# SN32F420 register map
Vendor: SONiX Technology Co., Ltd.; Series: SN32F420; File version: 1.00
CPU: CM0 r0p0, little endian, no MPU, no FPU, 2 interrupt priority bits
Registers are 32-bit, read-write, reset 0x0 unless marked. A register's access mark holds for its fields unless they carry their own. Offsets are from the block's base; [hi:lo] are bit positions; 'fields as' and 'values as' point back to an identical list.

## SN_UT16B0 — 16-bit Timer 0 with General Capture function
Base 0x40002000
Same registers: SN_UT16B1 0x40004000
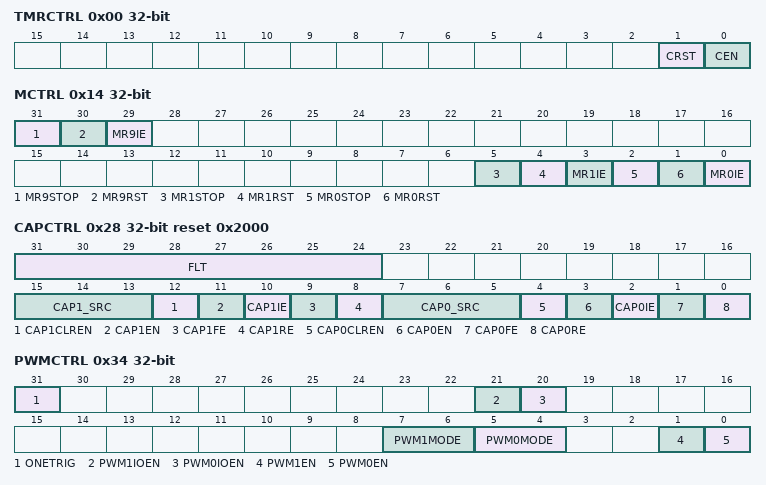
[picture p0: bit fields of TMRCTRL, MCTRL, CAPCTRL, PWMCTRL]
0x00 TMRCTRL — Offset:0x00 UT16Bn Timer Control register
  [1] CRST — Counter Reset
    0=Disable counter reset; 1=Reset Counter (Timer Counter and the Prescale Counter are synchronously reset on the next positive edge of PCLK)
  [0] CEN — Counter enable
    0=Disable counter; 1=Enable Timer Counter and Prescale Counter for counting
0x04 TC — Offset:0x04 UT16Bn Timer Counter register
  [15:0] TC — Timer Counter
0x08 PRE — Offset:0x08 UT16Bn Prescale register
  [7:0] PRE — Prescaler
0x0C PC — Offset:0x0C UT16Bn Prescale Counter register
  [7:0] PC — Prescaler Counter
0x10 CNTCTRL — Offset:0x10 UT16Bn Counter Control register
  [2:0] CTM — Counter/Timer Mode
    0=Timer Mode: every rising PCLK edge; 1=Counter Mode 1 (TC is incremented on rising edges on the CAP0_SIG); 2=Counter Mode 2 (TC is incremented on falling edges on the CAP0_SIG); 3=Counter Mode 3 (TC is incremented on both edges on the CAP0_SIG); 4=Counter Mode 4 (TC is incremented on rising edges on the CAP1_SIG); 5=Counter Mode 5 (TC is incremented on falling edges on the CAP1_SIG); 6=Counter Mode 6 (TC is incremented on both edges on the CAP1_SIG)
0x14 MCTRL — Offset:0x14 UT16Bn Match Control register
  [31] MR9STOP — Stop TC and PC and clear CEN bit when MR9 matches TC
    0=Disable stop TC and PC; 1=Enable (Stop TC and PC and clear CEN bit when MR9 matches TC)
  [30] MR9RST — Enable reset TC when MR9 matches TC
    0=Disable reset TC; 1=Enable (Reset TC when MR9 matches TC)
  [29] MR9IE — Enable generating an interrupt based on CM[2:0] when MR9 matches the value in the TC
    0=Disable generating an interrupt; 1=Enable (Generating an interrupt when MR9 matches TC)
  [5] MR1STOP — Stop TC and PC and clear CEN bit when MR1 matches TC
    0=Disable stop TC and PC; 1=Enable (Stop TC and PC and clear CEN bit when MR1 matches TC)
  [4] MR1RST — Enable reset TC when MR1 matches TC
    0=Disable reset TC; 1=Enable (Reset TC when MR1 matches TC)
  [3] MR1IE — Enable generating an interrupt when MR1 matches TC
    0=Disable generating an interrupt; 1=Enable (Generating an interrupt when MR1 matches TC)
  [2] MR0STOP — Stop TC and PC and clear CEN bit when MR0 matches TC
    0=Disable stop TC and PC; 1=Enable (Stop TC and PC and clear CEN bit when MR0 matches TC)
  [1] MR0RST — Enable reset TC when MR0 matches TC
    0=Disable reset TC; 1=Enable (Reset TC when MR0 matches TC)
  [0] MR0IE — Enable generating an interrupt when MR0 matches TC
    0=Disable generating an interrupt; 1=Enable (Generating an interrupt when MR0 matches TC)
0x18 MR0 — Offset:0x18 UT16Bn MR0 register
  [15:0] MR — Timer counter match value
0x1C MR1 — Offset:0x1C UT16Bn MR1 register
  [15:0] MR — Timer counter match value
0x28 CAPCTRL reset 0x2000 — Offset:0x28 UT16Bn Capture Control register
  [31:24] FLT — Filter width setting for CAP0/1 signal
  [15:13] CAP1_SRC — Signal source of capture event
    0=CAP0_F (Select the CAP0_F as signal source of CAP1_SIG); 1=CAP1_F (Select the CAP1_F as signal source of CAP1_SIG); 2=CAP_XOR (Select CAP0_F XOR CAP1_F as signal source of CAP1_SIG); 3=CMP0 OUT (Select CMP0 OUT as signal source of CAP1_SIG); 4=CMP1 OUT (Select CMP1 OUT as signal source of CAP1_SIG)
  [12] CAP1CLREN — Enable reset TC when capture event occurs.
    0=Disable reset TC when capture event occurs; 1=Enable reset TC when capture event occurs
  [11] CAP1EN — CAP1 function enable
    0=Disable capture function; 1=Enable CAP1 function for external Capture pin
  [10] CAP1IE — Interrupt on UT16Bn_CAP1 event
    0=Disable interrupt; 1=Enable (A CAP0 load due to a UT16Bn_CAP1 event will generate an interrupt.)
  [9] CAP1FE — Capture/Reset on UT16Bn_CAP1 signal falling edge
    0=Disable (No action); 1=Enable (Capture on CAP1_SIG falling edge)
  [8] CAP1RE — Capture/Reset on UT16Bn_CAP1 signal rising edge
    0=Disable (No action); 1=Enable (Capture on CAP1_SIG rising edge)
  [7:5] CAP0_SRC — Signal source of capture event
    0=CAP0_F (Select the CAP0_F as signal source of CAP0_SIG); 1=CAP1_F (Select the CAP1_F as signal source of CAP0_SIG); 2=CAP_XOR (Select CAP0_F XOR CAP1_F as signal source of CAP0_SIG); 3=CMP0 OUT (Select CMP0 OUT as signal source of CAP0_SIG); 4=CMP1 OUT (Select CMP1 OUT as signal source of CAP0_SIG)
  [4] CAP0CLREN — Enable reset TC when capture event occurs.
    values as CAP1CLREN
  [3] CAP0EN — CAP0 function enable
    0=Disable capture function; 1=Enable CAP0 function for external Capture pin
  [2] CAP0IE — Interrupt on UT16Bn_CAP0 event
    0=Disable interrupt; 1=Enable (A CAP0 load due to a UT16Bn_CAP0 event will generate an interrupt.)
  [1] CAP0FE — Capture/Reset on UT16Bn_CAP0 signal falling edge
    0=Disable (No action); 1=Enable (Capture on CAP0_SIG falling edge)
  [0] CAP0RE — Capture/Reset on UT16Bn_CAP0 signal rising edge
    0=Disable (No action); 1=Enable (Capture on CAP0_SIG rising edge)
0x2C CAP0 ro — Offset:0x2C UT16Bn CAP0 register
  [15:0] CAP0 — Timer counter capture value
0x30 CAP1 ro — Offset:0x30 UT16Bn CAP1 register
  [15:0] CAP1 — Timer counter capture value
0x34 PWMCTRL — Offset:0x34 UT16Bn PWM Control register
  [31] ONETRIG — One trigger mode
    0=Disable one trigger mode; 1=Enable one trigger mode
  [21] PWM1IOEN — UT16Bn_PWM1/GPIO selection
    0=Disable (UT16Bn_PWM1 pin is act as GPIO); 1=Enable (UT16Bn_PWM1 pin act as match output, and output depends on PWM1EN bit)
  [20] PWM0IOEN — UT16Bn_PWM0/GPIO selection
    0=Disable (UT16Bn_PWM0 pin is act as GPIO); 1=Enable (UT16Bn_PWM0 pin act as match output, and output depends on PWM0EN bit)
  [7:6] PWM1MODE — PWM1 output mode
    0=PWM mode 1 (During up-counting, PWM1 is 0 when TC is less than MR1.); 1=PWM mode 2 (During up-counting, PWM1 is 1 when TC is less than MR1.); 2=Force 0 (PWM1 is forced to 0); 3=Force 1 (PWM1 is forced to 1)
  [5:4] PWM0MODE — PWM0 output mode
    0=PWM mode 1 (During up-counting, PWM0 is 0 when TC is less than MR0.); 1=PWM mode 2 (During up-counting, PWM0 is 1 when TC is less than MR0.); 2=Force 0 (PWM0 is forced to 0); 3=Force 1 (PWM0 is forced to 1)
  [1] PWM1EN — PWM1 enable
    0=Disable PWM mode for UT16Bn_PWM1; 1=Enable PWM mode for UT16Bn_PWM1
  [0] PWM0EN — PWM0 enable
    0=Disable PWM mode for UT16Bn_PWM0; 1=Enable PWM mode for UT16Bn_PWM0
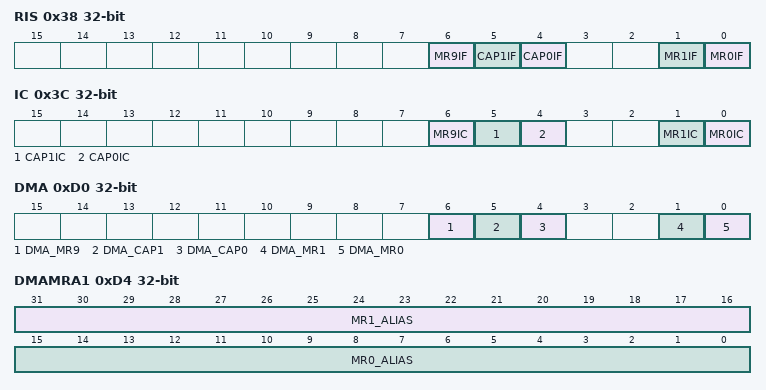
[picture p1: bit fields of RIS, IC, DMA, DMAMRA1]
0x38 RIS ro — Offset:0x38 UT16Bn Raw Interrupt Status register
  [6] MR9IF — Match channel 9 interrupt flag
    0=No (No interrupt on match channel 9); 1=Met interrupt requirements (Interrupt requirements met on match channel 9)
  [5] CAP1IF — Capture channel 1 interrupt flag
    0=No (No interrupt on CAP1); 1=Met interrupt requirements (Interrupt requirements met on CAP1)
  [4] CAP0IF — Capture channel 0 interrupt flag
    0=No (No interrupt on CAP0); 1=Met interrupt requirements (Interrupt requirements met on CAP0)
  [1] MR1IF — Match channel 1 interrupt flag
    0=No (No interrupt on match channel 1); 1=Met interrupt requirements (Interrupt requirements met on match channel 1)
  [0] MR0IF — Match channel 0 interrupt flag
    0=No (No interrupt on match channel 0); 1=Met interrupt requirements (Interrupt requirements met on match channel 0)
0x3C IC wo — Offset:0x3C UT16Bn Interrupt Clear register
  [6] MR9IC — MR9IF clear bit
    0=None (No effect); 1=Clear MR9IF
  [5] CAP1IC — CAP1IF clear bit
    0=None (No effect); 1=Clear CAP1IF
  [4] CAP0IC — CAP0IF clear bit
    0=None (No effect); 1=Clear CAP0IF
  [1] MR1IC — MR1IF clear bit
    0=None (No effect); 1=Clear MR1IF
  [0] MR0IC — MR0IF clear bit
    0=None (No effect); 1=Clear MR0IF
0x40 MR9 — Offset:0x40 UT16Bn MR9 register
  [15:0] MR — Timer counter match value
0xD0 DMA — Offset:0xD0 UT16Bn DMA mode register
  [6] DMA_MR9 — MR9 DMA request active enable
    0=Disable. MR9 DMA request cannot issue.; 1=Enable. MR9 DMA request can issue.
  [5] DMA_CAP1 — CAP1 DMA request active enable
    0=Disable. CAP1 DMA request cannot issue.; 1=Enable. CAP1 DMA request can issue.
  [4] DMA_CAP0 — CAP0 DMA request active enable
    0=Disable. CAP0 DMA request cannot issue.; 1=Enable. CAP0 DMA request can issue.
  [1] DMA_MR1 — MR1 DMA request active enable
    0=Disable. MR1 DMA request cannot issue.; 1=Enable. MR1 DMA request can issue.
  [0] DMA_MR0 — MR0 DMA request active enable
    0=Disable. MR0 DMA request cannot issue.; 1=Enable. MR0 DMA request can issue.
0xD4 DMAMRA1 wo — Offset:0xD4 UT16Bn DMA MR Alias register 1
  [31:16] MR1_ALIAS — MR1 alias for DMA access
  [15:0] MR0_ALIAS — MR0 alias for DMA access
